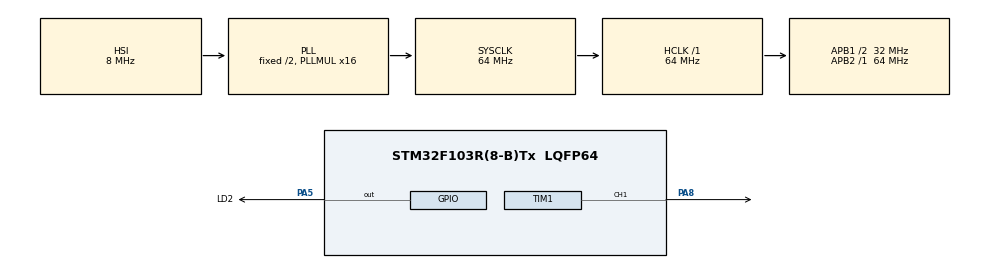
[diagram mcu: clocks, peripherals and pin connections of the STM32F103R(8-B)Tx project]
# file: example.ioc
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Mcu.Family=STM32F1
Mcu.Name=STM32F103R(8-B)Tx
Mcu.Package=LQFP64
NVIC.PriorityGroup=NVIC_PRIORITYGROUP_4
PA13.GPIO_Label=TMS
PA13.Mode=Serial_Wire
PA13.Signal=SYS_JTMS-SWDIO
PA14.GPIO_Label=TCK
PA14.Mode=Serial_Wire
PA14.Signal=SYS_JTCK-SWCLK
PA5.GPIO_Label=LD2
PA5.Signal=GPIO_Output
PA8.Signal=S_TIM1_CH1
ProjectManager.HeapSize=0x200
ProjectManager.StackSize=0x400
ProjectManager.TargetToolchain=SW4STM32
RCC.AHBFreq_Value=64000000
RCC.APB1CLKDivider=RCC_HCLK_DIV2
RCC.APB1Freq_Value=32000000
RCC.APB1TimFreq_Value=64000000
RCC.APB2Freq_Value=64000000
RCC.APB2TimFreq_Value=64000000
RCC.HCLKFreq_Value=64000000
RCC.PLLMUL=RCC_PLL_MUL16
RCC.RTCClockSelection=RCC_RTCCLKSOURCE_LSE
RCC.SYSCLKFreq_VALUE=64000000
RCC.SYSCLKSource=RCC_SYSCLKSOURCE_PLLCLK
RCC.USBFreq_Value=64000000
SH.S_TIM1_CH1.0=TIM1_CH1,PWM Generation1 CH1
TIM1.Channel-PWM\ Generation1\ CH1=TIM_CHANNEL_1
TIM1.Period=63999
TIM1.Pulse-PWM\ Generation1\ CH1=32000
board=NUCLEO-F103RB

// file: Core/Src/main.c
/* USER CODE BEGIN Header */
/**
  ******************************************************************************
  * @file           : main.c
  * @brief          : Main program body
  ******************************************************************************
  * @attention
  *
  * <h2><center>&copy; Copyright (c) 2021 STMicroelectronics.
  * All rights reserved.</center></h2>
  *
  * This software component is licensed by ST under BSD 3-Clause license,
  * the "License"; You may not use this file except in compliance with the
  * License. You may obtain a copy of the License at:
  *                        opensource.org/licenses/BSD-3-Clause
  *
  ******************************************************************************
  */
/* USER CODE END Header */
#include "main.h"

TIM_HandleTypeDef htim1;

void SystemClock_Config(void);
static void MX_GPIO_Init(void);
static void MX_TIM1_Init(void);

int main(void)
{

  /* MCU Configuration--------------------------------------------------------*/

  /* Reset of all peripherals, Initializes the Flash interface and the Systick. */
  HAL_Init();

  /* Configure the system clock */
  SystemClock_Config();

  /* Initialize all configured peripherals */
  MX_GPIO_Init();
  MX_TIM1_Init();
  /* USER CODE BEGIN 2 */
  HAL_TIM_PWM_Start(&htim1,TIM_CHANNEL_1);

  // Counter for 50% duty cycle
  TIM1->CCR1 = 31999;

  // Counter for 30% duty cycle
    TIM1->CCR1 = 19199;

  /* USER CODE END 2 */

  /* Infinite loop */
  while (1)
  {

  }
}

void SystemClock_Config(void)
{
  RCC_OscInitTypeDef RCC_OscInitStruct = {0};
  RCC_ClkInitTypeDef RCC_ClkInitStruct = {0};

  /** Initializes the RCC Oscillators according to the specified parameters
  * in the RCC_OscInitTypeDef structure.
  */
  RCC_OscInitStruct.OscillatorType = RCC_OSCILLATORTYPE_HSI;
  RCC_OscInitStruct.HSIState = RCC_HSI_ON;
  RCC_OscInitStruct.HSICalibrationValue = RCC_HSICALIBRATION_DEFAULT;
  RCC_OscInitStruct.PLL.PLLState = RCC_PLL_ON;
  RCC_OscInitStruct.PLL.PLLSource = RCC_PLLSOURCE_HSI_DIV2;
  RCC_OscInitStruct.PLL.PLLMUL = RCC_PLL_MUL16;
  if (HAL_RCC_OscConfig(&RCC_OscInitStruct) != HAL_OK)
  {
    Error_Handler();
  }
  /** Initializes the CPU, AHB and APB buses clocks
  */
  RCC_ClkInitStruct.ClockType = RCC_CLOCKTYPE_HCLK|RCC_CLOCKTYPE_SYSCLK
                              |RCC_CLOCKTYPE_PCLK1|RCC_CLOCKTYPE_PCLK2;
  RCC_ClkInitStruct.SYSCLKSource = RCC_SYSCLKSOURCE_PLLCLK;
  RCC_ClkInitStruct.AHBCLKDivider = RCC_SYSCLK_DIV1;
  RCC_ClkInitStruct.APB1CLKDivider = RCC_HCLK_DIV2;
  RCC_ClkInitStruct.APB2CLKDivider = RCC_HCLK_DIV1;

  if (HAL_RCC_ClockConfig(&RCC_ClkInitStruct, FLASH_LATENCY_2) != HAL_OK)
  {
    Error_Handler();
  }
}

static void MX_TIM1_Init(void)
{

  TIM_MasterConfigTypeDef sMasterConfig = {0};
  TIM_OC_InitTypeDef sConfigOC = {0};
  TIM_BreakDeadTimeConfigTypeDef sBreakDeadTimeConfig = {0};

  htim1.Instance = TIM1;
  htim1.Init.Prescaler = 0;
  htim1.Init.CounterMode = TIM_COUNTERMODE_UP;
  htim1.Init.Period = 63999;
  htim1.Init.ClockDivision = TIM_CLOCKDIVISION_DIV1;
  htim1.Init.RepetitionCounter = 0;
  htim1.Init.AutoReloadPreload = TIM_AUTORELOAD_PRELOAD_DISABLE;
  if (HAL_TIM_PWM_Init(&htim1) != HAL_OK)
  {
    Error_Handler();
  }
  sMasterConfig.MasterOutputTrigger = TIM_TRGO_RESET;
  sMasterConfig.MasterSlaveMode = TIM_MASTERSLAVEMODE_DISABLE;
  if (HAL_TIMEx_MasterConfigSynchronization(&htim1, &sMasterConfig) != HAL_OK)
  {
    Error_Handler();
  }
  sConfigOC.OCMode = TIM_OCMODE_PWM1;
  sConfigOC.Pulse = 32000;
  sConfigOC.OCPolarity = TIM_OCPOLARITY_HIGH;
  sConfigOC.OCNPolarity = TIM_OCNPOLARITY_HIGH;
  sConfigOC.OCFastMode = TIM_OCFAST_DISABLE;
  sConfigOC.OCIdleState = TIM_OCIDLESTATE_RESET;
  sConfigOC.OCNIdleState = TIM_OCNIDLESTATE_RESET;
  if (HAL_TIM_PWM_ConfigChannel(&htim1, &sConfigOC, TIM_CHANNEL_1) != HAL_OK)
  {
    Error_Handler();
  }
  sBreakDeadTimeConfig.OffStateRunMode = TIM_OSSR_DISABLE;
  sBreakDeadTimeConfig.OffStateIDLEMode = TIM_OSSI_DISABLE;
  sBreakDeadTimeConfig.LockLevel = TIM_LOCKLEVEL_OFF;
  sBreakDeadTimeConfig.DeadTime = 0;
  sBreakDeadTimeConfig.BreakState = TIM_BREAK_DISABLE;
  sBreakDeadTimeConfig.BreakPolarity = TIM_BREAKPOLARITY_HIGH;
  sBreakDeadTimeConfig.AutomaticOutput = TIM_AUTOMATICOUTPUT_DISABLE;
  if (HAL_TIMEx_ConfigBreakDeadTime(&htim1, &sBreakDeadTimeConfig) != HAL_OK)
  {
    Error_Handler();
  }
  HAL_TIM_MspPostInit(&htim1);

}

static void MX_GPIO_Init(void)
{
  GPIO_InitTypeDef GPIO_InitStruct = {0};

  /* GPIO Ports Clock Enable */
  __HAL_RCC_GPIOC_CLK_ENABLE();
  __HAL_RCC_GPIOD_CLK_ENABLE();
  __HAL_RCC_GPIOA_CLK_ENABLE();
  __HAL_RCC_GPIOB_CLK_ENABLE();

  /*Configure GPIO pin Output Level */
  HAL_GPIO_WritePin(LD2_GPIO_Port, LD2_Pin, GPIO_PIN_RESET);

  /*Configure GPIO pins : PC13 PC14 PC15 PC0
                           PC1 PC2 PC3 PC4
                           PC5 PC6 PC7 PC8
                           PC9 PC10 PC11 PC12 */
  GPIO_InitStruct.Pin = GPIO_PIN_13|GPIO_PIN_14|GPIO_PIN_15|GPIO_PIN_0
                          |GPIO_PIN_1|GPIO_PIN_2|GPIO_PIN_3|GPIO_PIN_4
                          |GPIO_PIN_5|GPIO_PIN_6|GPIO_PIN_7|GPIO_PIN_8
                          |GPIO_PIN_9|GPIO_PIN_10|GPIO_PIN_11|GPIO_PIN_12;
  GPIO_InitStruct.Mode = GPIO_MODE_ANALOG;
  HAL_GPIO_Init(GPIOC, &GPIO_InitStruct);

  /*Configure GPIO pins : PD0 PD1 PD2 */
  GPIO_InitStruct.Pin = GPIO_PIN_0|GPIO_PIN_1|GPIO_PIN_2;
  GPIO_InitStruct.Mode = GPIO_MODE_ANALOG;
  HAL_GPIO_Init(GPIOD, &GPIO_InitStruct);

  /*Configure GPIO pins : PA0 PA1 PA2 PA3
                           PA4 PA6 PA7 PA9
                           PA10 PA11 PA12 PA15 */
  GPIO_InitStruct.Pin = GPIO_PIN_0|GPIO_PIN_1|GPIO_PIN_2|GPIO_PIN_3
                          |GPIO_PIN_4|GPIO_PIN_6|GPIO_PIN_7|GPIO_PIN_9
                          |GPIO_PIN_10|GPIO_PIN_11|GPIO_PIN_12|GPIO_PIN_15;
  GPIO_InitStruct.Mode = GPIO_MODE_ANALOG;
  HAL_GPIO_Init(GPIOA, &GPIO_InitStruct);

  /*Configure GPIO pin : LD2_Pin */
  GPIO_InitStruct.Pin = LD2_Pin;
  GPIO_InitStruct.Mode = GPIO_MODE_OUTPUT_PP;
  GPIO_InitStruct.Pull = GPIO_NOPULL;
  GPIO_InitStruct.Speed = GPIO_SPEED_FREQ_LOW;
  HAL_GPIO_Init(LD2_GPIO_Port, &GPIO_InitStruct);

  /*Configure GPIO pins : PB0 PB1 PB2 PB10
                           PB11 PB12 PB13 PB14
                           PB15 PB3 PB4 PB5
                           PB6 PB7 PB8 PB9 */
  GPIO_InitStruct.Pin = GPIO_PIN_0|GPIO_PIN_1|GPIO_PIN_2|GPIO_PIN_10
                          |GPIO_PIN_11|GPIO_PIN_12|GPIO_PIN_13|GPIO_PIN_14
                          |GPIO_PIN_15|GPIO_PIN_3|GPIO_PIN_4|GPIO_PIN_5
                          |GPIO_PIN_6|GPIO_PIN_7|GPIO_PIN_8|GPIO_PIN_9;
  GPIO_InitStruct.Mode = GPIO_MODE_ANALOG;
  HAL_GPIO_Init(GPIOB, &GPIO_InitStruct);

  /*Configure peripheral I/O remapping */
  __HAL_AFIO_REMAP_PD01_ENABLE();

}

void Error_Handler(void)
{
  __disable_irq();
  while (1)
  {
  }
}

/************************ (C) COPYRIGHT STMicroelectronics *****END OF FILE****/
